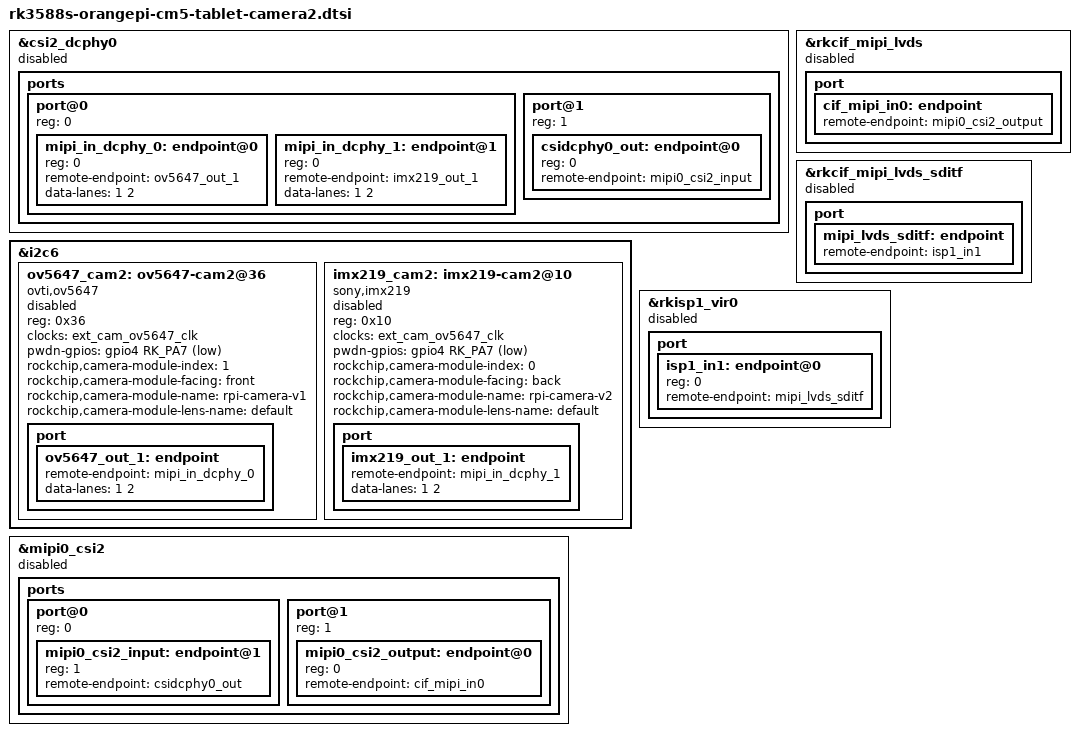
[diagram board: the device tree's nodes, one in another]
// SPDX-License-Identifier: (GPL-2.0+ OR MIT)
/*
 * Copyright (c) 2021 Rockchip Electronics Co., Ltd.
 *
 */

&csi2_dcphy0 {
	status = "disabled";

	ports {
		#address-cells = <1>;
		#size-cells = <0>;
		port@0 {
			reg = <0>;
			#address-cells = <1>;
			#size-cells = <0>;

			mipi_in_dcphy_0: endpoint@0 {
				reg = <0>;
				remote-endpoint = <&ov5647_out_1>;
				data-lanes = <1 2>;
			};

			mipi_in_dcphy_1: endpoint@1 {
				reg = <0>;
				remote-endpoint = <&imx219_out_1>;
				data-lanes = <1 2>;
			};
		};

		port@1 {
			reg = <1>;
			#address-cells = <1>;
			#size-cells = <0>;

			csidcphy0_out: endpoint@0 {
				reg = <0>;
				remote-endpoint = <&mipi0_csi2_input>;
			};
		};
	};
};

&i2c6 {
	status = "okay";

	ov5647_cam2: ov5647-cam2@36 {
		status = "disabled";
		compatible = "ovti,ov5647";
		reg = <0x36>;
		clocks = <&ext_cam_ov5647_clk>;
		clock-names = "ext_cam_ov5647_clk";
		pwdn-gpios = <&gpio4 RK_PA7 GPIO_ACTIVE_LOW>;
		rockchip,camera-module-index = <1>;
		rockchip,camera-module-facing = "front";
		rockchip,camera-module-name = "rpi-camera-v1";
		rockchip,camera-module-lens-name = "default";
		port {
			ov5647_out_1: endpoint {
			        remote-endpoint = <&mipi_in_dcphy_0>;
			        data-lanes = <1 2>;
			};
		};
	};

	imx219_cam2: imx219-cam2@10 {
	        status = "disabled";
	        compatible = "sony,imx219";
	        reg = <0x10>;
	        clocks = <&ext_cam_ov5647_clk>;
	        clock-names = "ext_cam_ov5647_clk";
	        pwdn-gpios = <&gpio4 RK_PA7 GPIO_ACTIVE_LOW>;
	        rockchip,camera-module-index = <0>;
	        rockchip,camera-module-facing = "back";
	        rockchip,camera-module-name = "rpi-camera-v2";
	        rockchip,camera-module-lens-name = "default";
	        port {
	                imx219_out_1: endpoint {
			        remote-endpoint = <&mipi_in_dcphy_1>;
	                        data-lanes = <1 2>;
	                };
	        };
	};
};

&mipi0_csi2 {
	status = "disabled";

	ports {
		#address-cells = <1>;
		#size-cells = <0>;

		port@0 {
			reg = <0>;
			#address-cells = <1>;
			#size-cells = <0>;

			mipi0_csi2_input: endpoint@1 {
				reg = <1>;
				remote-endpoint = <&csidcphy0_out>;
			};
		};

		port@1 {
			reg = <1>;
			#address-cells = <1>;
			#size-cells = <0>;

			mipi0_csi2_output: endpoint@0 {
				reg = <0>;
				remote-endpoint = <&cif_mipi_in0>;
			};
		};
	};
};

&rkcif_mipi_lvds {
	status = "disabled";

	port {
		cif_mipi_in0: endpoint {
			remote-endpoint = <&mipi0_csi2_output>;
		};
	};
};

&rkcif_mipi_lvds_sditf {
	status = "disabled";

	port {
		mipi_lvds_sditf: endpoint {
			remote-endpoint = <&isp1_in1>;
		};
	};
};

&rkisp1_vir0 {
	status = "disabled";

	port {
		#address-cells = <1>;
		#size-cells = <0>;

		isp1_in1: endpoint@0 {
			reg = <0>;
			remote-endpoint = <&mipi_lvds_sditf>;
		};
	};
};
